# ATtiny1634 register map
Vendor: Atmel; File version: 1.0
CPU: other r0p0, little endian, no MPU, no FPU, 4 interrupt priority bits
Registers are 8-bit, read-write, reset 0x0 unless marked. A register's access mark holds for its fields unless they carry their own. Offsets are from the block's base; [hi:lo] are bit positions.

## TWI — Two Wire Serial Interface
Base 0x0080007A
0x00 TWSD — TWI Slave Data Register (read-only for debugger)
  [7:0] TWSD — TWI slave data bit
0x01 TWSAM — TWI Slave Address Mask Register
0x02 TWSA — TWI Slave Address Register (read-only for debugger)
  [7:0] TWSA — TWI slave address bit
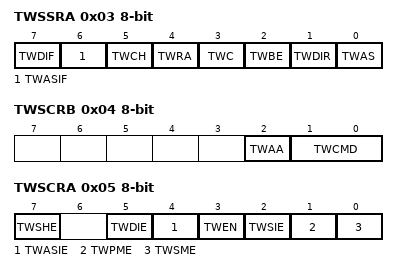
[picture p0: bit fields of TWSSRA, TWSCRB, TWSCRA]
0x03 TWSSRA — TWI Slave Status Register A
  [7] TWDIF — TWI Data Interrupt Flag
  [6] TWASIF — TWI Address/Stop Interrupt Flag
  [5] TWCH — TWI Clock Hold
  [4] TWRA — TWI Receive Acknowledge
  [3] TWC — TWI Collision
  [2] TWBE — TWI Bus Error
  [1] TWDIR — TWI Read/Write Direction
  [0] TWAS — TWI Address or Stop
0x04 TWSCRB — TWI Slave Control Register B
  [2] TWAA — TWI Acknowledge Action
  [1:0] TWCMD
0x05 TWSCRA — TWI Slave Control Register A
  [7] TWSHE — TWI SDA Hold Time Enable
  [5] TWDIE — TWI Data Interrupt Enable
  [4] TWASIE — TWI Address/Stop Interrupt Enable
  [3] TWEN — Two-Wire Interface Enable
  [2] TWSIE — TWI Stop Interrupt Enable
  [1] TWPME — TWI Promiscuous Mode Enable
  [0] TWSME — TWI Smart Mode Enable

## USART0 — USART
Base 0x00800040
0x00 UDR0 — USART I/O Data Register (write-only for debugger)
0x01 UBRR0 16-bit (reset mask 0xFF) — USART Baud Rate Register Bytes
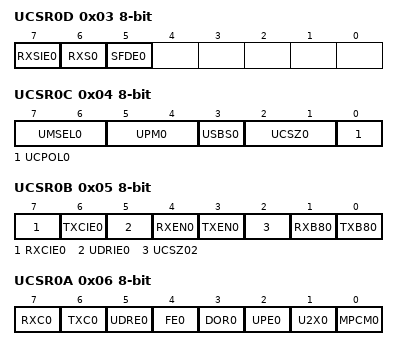
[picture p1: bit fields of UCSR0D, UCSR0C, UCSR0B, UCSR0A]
0x03 UCSR0D — USART Control and Status Register D
  [7] RXSIE0 — USART RX Start Interrupt Enable
  [6] RXS0 — USART RX Start Flag
  [5] SFDE0 — USART RX Start Frame Detection Enable
0x04 UCSR0C — USART Control and Status Register C
  [7:6] UMSEL0 — USART Mode Select
    0=ASYNCHRONOUS_USART; 1=SYNCHRONOUS_USART; 3=MASTER_SPI
  [5:4] UPM0 — Parity Mode Bits
    0=DISABLED; 2=ENABLED_EVEN_PARITY; 3=ENABLED_ODD_PARITY
  [3] USBS0 — Stop Bit Select
    0=1_BIT; 1=2_BIT
  [2:1] UCSZ0 — Character Size
  [0] UCPOL0 — Clock Polarity
0x05 UCSR0B — USART Control and Status Register B
  [7] RXCIE0 — RX Complete Interrupt Enable
  [6] TXCIE0 — TX Complete Interrupt Enable
  [5] UDRIE0 — USART Data register Empty Interrupt Enable
  [4] RXEN0 — Receiver Enable
  [3] TXEN0 — Transmitter Enable
  [2] UCSZ02 — Character Size
  [1] RXB80 — Receive Data Bit 8
  [0] TXB80 — Transmit Data Bit 8
0x06 UCSR0A — USART Control and Status Register A (read-only for debugger)
  [7] RXC0 ro — USART Receive Complete
  [6] TXC0 — USART Transmit Complete
  [5] UDRE0 ro — USART Data Register Empty
  [4] FE0 ro — Framing Error
  [3] DOR0 ro — Data overRun
  [2] UPE0 ro — Parity Error
  [1] U2X0 — Double the USART transmission speed
  [0] MPCM0 — Multi-processor Communication Mode

## USART1 — USART
Base 0x00800073
0x00 UDR1 — USART I/O Data Register (write-only for debugger)
0x01 UBRR1 16-bit (reset mask 0xFF) — USART Baud Rate Register Bytes
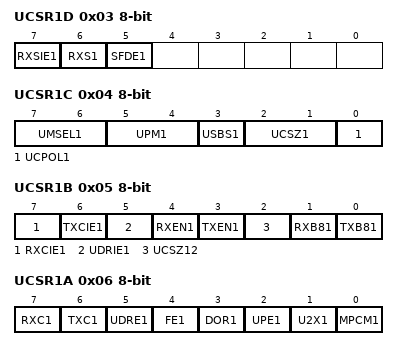
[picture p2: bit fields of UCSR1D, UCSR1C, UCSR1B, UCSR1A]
0x03 UCSR1D — USART Control and Status Register D
  [7] RXSIE1 — USART RX Start Interrupt Enable
  [6] RXS1 — USART RX Start Flag
  [5] SFDE1 — USART RX Start Frame Detection Enable
0x04 UCSR1C — USART Control and Status Register C
  [7:6] UMSEL1 — USART Mode Select
    0=ASYNCHRONOUS_USART; 1=SYNCHRONOUS_USART; 3=MASTER_SPI
  [5:4] UPM1 — Parity Mode Bits
    0=DISABLED; 2=ENABLED_EVEN_PARITY; 3=ENABLED_ODD_PARITY
  [3] USBS1 — Stop Bit Select
    0=1_BIT; 1=2_BIT
  [2:1] UCSZ1 — Character Size
  [0] UCPOL1 — Clock Polarity
0x05 UCSR1B — USART Control and Status Register B
  [7] RXCIE1 — RX Complete Interrupt Enable
  [6] TXCIE1 — TX Complete Interrupt Enable
  [5] UDRIE1 — USART Data register Empty Interrupt Enable
  [4] RXEN1 — Receiver Enable
  [3] TXEN1 — Transmitter Enable
  [2] UCSZ12 — Character Size
  [1] RXB81 — Receive Data Bit 8
  [0] TXB81 — Transmit Data Bit 8
0x06 UCSR1A — USART Control and Status Register A (read-only for debugger)
  [7] RXC1 — USART Receive Complete
  [6] TXC1 — USART Transmit Complete
  [5] UDRE1 — USART Data Register Empty
  [4] FE1 — Framing Error
  [3] DOR1 — Data overRun
  [2] UPE1 — Parity Error
  [1] U2X1 — Double the USART transmission speed
  [0] MPCM1 — Multi-processor Communication Mode

## USI — Universal Serial Interface
Base 0x0080004A
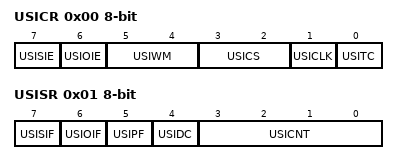
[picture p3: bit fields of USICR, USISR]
0x00 USICR — USI Control Register
  [7] USISIE — Start Condition Interrupt Enable
  [6] USIOIE — Counter Overflow Interrupt Enable
  [5:4] USIWM — USI Wire Mode Bits
    0=NORMAL_OPERATION; 1=THREE_WIRE_MODE; 2=TWO_WIRE_MODE; 3=TWO_WIRE_MODE_HELD_LOW
  [3:2] USICS — USI Clock Source Select Bits
  [1] USICLK — Clock Strobe
  [0] USITC — Toggle Clock Port Pin
0x01 USISR — USI Status Register (read-only for debugger)
  [7] USISIF — Start Condition Interrupt Flag
  [6] USIOIF — Counter Overflow Interrupt Flag
  [5] USIPF — Stop Condition Flag
  [4] USIDC — Data Output Collision
  [3:0] USICNT — USI Counter Value Bits
0x02 USIDR — USI Data Register
0x03 USIBR — USI Buffer Register (read-only for debugger)

## WDT — Watchdog Timer
Base 0x00800050
0x00 WDTCSR — Watchdog Timer Control and Status Register
  [7] WDIF — Watchdog Timer Interrupt Flag
  [6] WDIE — Watchdog Timer Interrupt Enable
  [3] WDE — Watch Dog Enable
  [5:0] WDP — Watchdog Timer Prescaler Bits
    0=OSCILLATOR_CYCLES_512_16_MS; 1=OSCILLATOR_CYCLES_1K_32_MS; 2=OSCILLATOR_CYCLES_2K_64_MS; 3=OSCILLATOR_CYCLES_4K_0_125_S; 4=OSCILLATOR_CYCLES_8K_0_25_S; 5=OSCILLATOR_CYCLES_16K_0_5_S; 6=OSCILLATOR_CYCLES_32K_1_0_S; 7=OSCILLATOR_CYCLES_64K_2_0_S
